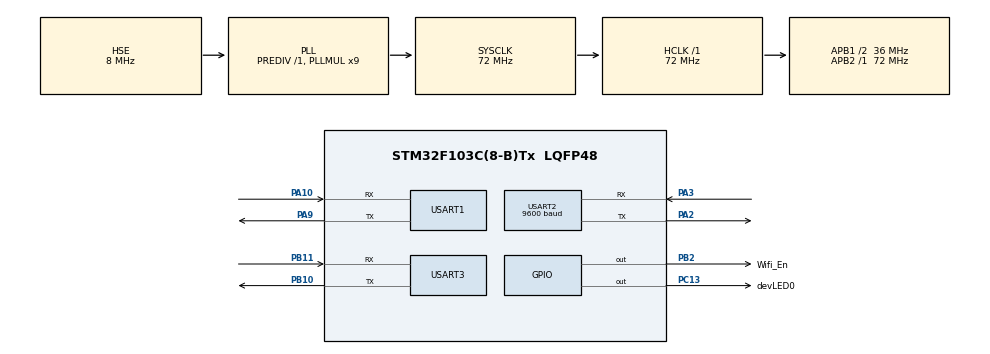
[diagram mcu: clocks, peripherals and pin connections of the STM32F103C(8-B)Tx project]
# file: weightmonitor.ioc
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Dma.Request0=USART1_RX
Dma.Request1=USART1_TX
Dma.Request2=USART3_RX
Dma.Request3=USART3_TX
Dma.Request4=USART2_RX
Dma.Request5=USART2_TX
Dma.USART1_RX.0.Direction=DMA_PERIPH_TO_MEMORY
Dma.USART1_RX.0.Instance=DMA1_Channel5
Dma.USART1_RX.0.MemDataAlignment=DMA_MDATAALIGN_BYTE
Dma.USART1_RX.0.MemInc=DMA_MINC_ENABLE
Dma.USART1_RX.0.Mode=DMA_CIRCULAR
Dma.USART1_RX.0.PeriphDataAlignment=DMA_PDATAALIGN_BYTE
Dma.USART1_RX.0.PeriphInc=DMA_PINC_DISABLE
Dma.USART1_RX.0.Priority=DMA_PRIORITY_LOW
Dma.USART1_TX.1.Direction=DMA_MEMORY_TO_PERIPH
Dma.USART1_TX.1.Instance=DMA1_Channel4
Dma.USART1_TX.1.MemDataAlignment=DMA_MDATAALIGN_BYTE
Dma.USART1_TX.1.MemInc=DMA_MINC_ENABLE
Dma.USART1_TX.1.Mode=DMA_NORMAL
Dma.USART1_TX.1.PeriphDataAlignment=DMA_PDATAALIGN_BYTE
Dma.USART1_TX.1.PeriphInc=DMA_PINC_DISABLE
Dma.USART1_TX.1.Priority=DMA_PRIORITY_LOW
Dma.USART2_RX.4.Direction=DMA_PERIPH_TO_MEMORY
Dma.USART2_RX.4.Instance=DMA1_Channel6
Dma.USART2_RX.4.MemDataAlignment=DMA_MDATAALIGN_BYTE
Dma.USART2_RX.4.MemInc=DMA_MINC_ENABLE
Dma.USART2_RX.4.Mode=DMA_CIRCULAR
Dma.USART2_RX.4.PeriphDataAlignment=DMA_PDATAALIGN_BYTE
Dma.USART2_RX.4.PeriphInc=DMA_PINC_DISABLE
Dma.USART2_RX.4.Priority=DMA_PRIORITY_LOW
Dma.USART2_TX.5.Direction=DMA_MEMORY_TO_PERIPH
Dma.USART2_TX.5.Instance=DMA1_Channel7
Dma.USART2_TX.5.MemDataAlignment=DMA_MDATAALIGN_BYTE
Dma.USART2_TX.5.MemInc=DMA_MINC_ENABLE
Dma.USART2_TX.5.Mode=DMA_NORMAL
Dma.USART2_TX.5.PeriphDataAlignment=DMA_PDATAALIGN_BYTE
Dma.USART2_TX.5.PeriphInc=DMA_PINC_DISABLE
Dma.USART2_TX.5.Priority=DMA_PRIORITY_LOW
Dma.USART3_RX.2.Direction=DMA_PERIPH_TO_MEMORY
Dma.USART3_RX.2.Instance=DMA1_Channel3
Dma.USART3_RX.2.MemDataAlignment=DMA_MDATAALIGN_BYTE
Dma.USART3_RX.2.MemInc=DMA_MINC_ENABLE
Dma.USART3_RX.2.Mode=DMA_CIRCULAR
Dma.USART3_RX.2.PeriphDataAlignment=DMA_PDATAALIGN_BYTE
Dma.USART3_RX.2.PeriphInc=DMA_PINC_DISABLE
Dma.USART3_RX.2.Priority=DMA_PRIORITY_LOW
Dma.USART3_TX.3.Direction=DMA_MEMORY_TO_PERIPH
Dma.USART3_TX.3.Instance=DMA1_Channel2
Dma.USART3_TX.3.MemDataAlignment=DMA_MDATAALIGN_BYTE
Dma.USART3_TX.3.MemInc=DMA_MINC_ENABLE
Dma.USART3_TX.3.Mode=DMA_NORMAL
Dma.USART3_TX.3.PeriphDataAlignment=DMA_PDATAALIGN_BYTE
Dma.USART3_TX.3.PeriphInc=DMA_PINC_DISABLE
Dma.USART3_TX.3.Priority=DMA_PRIORITY_LOW
FREERTOS.BinarySemaphores01=data_t_cplt;wifi_t_cplt;ctrl_t_cplt
FREERTOS.INCLUDE_vTaskDelayUntil=1
FREERTOS.Queues01=data_r_queue,4,uart_memblk_pt,NULL;data_t_queue,4,uart_memblk_pt,NULL;wifi_r_queue,4,uart_memblk_pt ,NULL;wifi_t_queue,4,uart_memblk_pt,NULL;ctrl_r_queue,4,uart_memblk_pt,NULL;ctrl_t_queue,4,uart_memblk_pt ,NULL;datarecv_queue,256,char,NULL;wifirecv_queue,256,char,NULL
FREERTOS.Tasks01=defaultTask,-3,128,StartDefaultTask,Default;recv_data,3,128,func_recv_data,As external;recv_ctrl,3,128,func_recv_ctrl,As external;recv_wifi,3,128,func_recv_wifi,As external;handle_data,1,128,func_handle_data,As external;handle_ctrl,1,128,func_handle_ctrl,As external;handle_wifi,1,128,func_handle_wifi,As external;send_data,2,128,func_send_data,As external;send_ctrl,2,128,func_send_ctrl,As external;send_wifi,2,128,func_send_wifi,As external;mainthread,0,128,func_mainthread,As external
FREERTOS.Timers01=led0,Callback_led0,osTimerOnce,As external
FREERTOS.configMINIMAL_STACK_SIZE=128
FREERTOS.configTIMER_TASK_PRIORITY=3
FREERTOS.configTOTAL_HEAP_SIZE=15360
FREERTOS.configUSE_TIMERS=1
IWDG.Prescaler=IWDG_PRESCALER_256
Mcu.Family=STM32F1
Mcu.Name=STM32F103C(8-B)Tx
Mcu.Package=LQFP48
NVIC.DMA1_Channel2_IRQn=true\:5\:0\:false
NVIC.DMA1_Channel3_IRQn=true\:5\:0\:false
NVIC.DMA1_Channel4_IRQn=true\:5\:0\:false
NVIC.DMA1_Channel5_IRQn=true\:5\:0\:false
NVIC.DMA1_Channel6_IRQn=true\:5\:0\:false
NVIC.DMA1_Channel7_IRQn=true\:5\:0\:false
NVIC.PriorityGroup=NVIC_PRIORITYGROUP_4
NVIC.TIM2_IRQn=true\:0\:0\:false
NVIC.TimeBase=TIM2_IRQn
NVIC.TimeBaseIP=TIM2
NVIC.USART1_IRQn=true\:5\:0\:false
NVIC.USART2_IRQn=true\:5\:0\:false
NVIC.USART3_IRQn=true\:5\:0\:false
PA10.GPIO_PuPd=GPIO_PULLDOWN
PA10.Mode=Asynchronous
PA10.Signal=USART1_RX
PA13.Mode=Serial_Wire
PA13.Signal=SYS_JTMS-SWDIO
PA14.Mode=Serial_Wire
PA14.Signal=SYS_JTCK-SWCLK
PA2.Mode=Asynchronous
PA2.Signal=USART2_TX
PA3.GPIO_PuPd=GPIO_PULLDOWN
PA3.Mode=Asynchronous
PA3.Signal=USART2_RX
PA9.Mode=Asynchronous
PA9.Signal=USART1_TX
PB10.Mode=Asynchronous
PB10.Signal=USART3_TX
PB11.GPIO_PuPd=GPIO_PULLDOWN
PB11.Mode=Asynchronous
PB11.Signal=USART3_RX
PB2.GPIO_Label=Wifi_En
PB2.Signal=GPIO_Output
PC13-TAMPER-RTC.GPIO_Label=devLED0
PC13-TAMPER-RTC.Signal=GPIO_Output
PD0-OSC_IN.Mode=HSE-External-Oscillator
PD0-OSC_IN.Signal=RCC_OSC_IN
PD1-OSC_OUT.Mode=HSE-External-Oscillator
PD1-OSC_OUT.Signal=RCC_OSC_OUT
ProjectManager.HeapSize=0x400
ProjectManager.StackSize=0x200
ProjectManager.TargetToolchain=MDK-ARM V5
RCC.AHBFreq_Value=72000000
RCC.APB1CLKDivider=RCC_HCLK_DIV2
RCC.APB1Freq_Value=36000000
RCC.APB1TimFreq_Value=72000000
RCC.APB2Freq_Value=72000000
RCC.APB2TimFreq_Value=72000000
RCC.HCLKFreq_Value=72000000
RCC.HSIState=RCC_HSI_ON
RCC.PLLMUL=RCC_PLL_MUL9
RCC.PLLSourceVirtual=RCC_PLLSOURCE_HSE
RCC.RTCClockSelection=RCC_RTCCLKSOURCE_LSE
RCC.SYSCLKFreq_VALUE=72000000
RCC.SYSCLKSource=RCC_SYSCLKSOURCE_PLLCLK
RCC.USBFreq_Value=48000000
RCC.USBPrescaler=RCC_USBPLLCLK_DIV1_5
USART2.BaudRate=9600
VP_FREERTOS_VS_ENABLE.Mode=Enabled
VP_IWDG_VS_IWDG.Mode=IWDG_Activate
VP_SYS_VS_tim2.Mode=TIM2
board=weightmonitor

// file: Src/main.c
/**
  ******************************************************************************
  * File Name          : main.c
  * Description        : Main program body
  ******************************************************************************
  *
  * COPYRIGHT(c) 2016 STMicroelectronics
  *
  * Redistribution and use in source and binary forms, with or without modification,
  * are permitted provided that the following conditions are met:
  *   1. Redistributions of source code must retain the above copyright notice,
  *      this list of conditions and the following disclaimer.
  *   2. Redistributions in binary form must reproduce the above copyright notice,
  *      this list of conditions and the following disclaimer in the documentation
  *      and/or other materials provided with the distribution.
  *   3. Neither the name of STMicroelectronics nor the names of its contributors
  *      may be used to endorse or promote products derived from this software
  *      without specific prior written permission.
  *
  * THIS SOFTWARE IS PROVIDED BY THE COPYRIGHT HOLDERS AND CONTRIBUTORS "AS IS"
  * AND ANY EXPRESS OR IMPLIED WARRANTIES, INCLUDING, BUT NOT LIMITED TO, THE
  * IMPLIED WARRANTIES OF MERCHANTABILITY AND FITNESS FOR A PARTICULAR PURPOSE ARE
  * DISCLAIMED. IN NO EVENT SHALL THE COPYRIGHT HOLDER OR CONTRIBUTORS BE LIABLE
  * FOR ANY DIRECT, INDIRECT, INCIDENTAL, SPECIAL, EXEMPLARY, OR CONSEQUENTIAL
  * DAMAGES (INCLUDING, BUT NOT LIMITED TO, PROCUREMENT OF SUBSTITUTE GOODS OR
  * SERVICES; LOSS OF USE, DATA, OR PROFITS; OR BUSINESS INTERRUPTION) HOWEVER
  * CAUSED AND ON ANY THEORY OF LIABILITY, WHETHER IN CONTRACT, STRICT LIABILITY,
  * OR TORT (INCLUDING NEGLIGENCE OR OTHERWISE) ARISING IN ANY WAY OUT OF THE USE
  * OF THIS SOFTWARE, EVEN IF ADVISED OF THE POSSIBILITY OF SUCH DAMAGE.
  *
  ******************************************************************************
  */
#include "stm32f1xx_hal.h"
#include "cmsis_os.h"
#include "dma.h"
#include "iwdg.h"
#include "usart.h"
#include "gpio.h"

/* USER CODE BEGIN Includes */
#include <stdbool.h>
#include "ledctrl.h"
#include "memblk.h"
/* USER CODE END Includes */

/* USER CODE BEGIN PV */
/* Private variables ---------------------------------------------------------*/

/* USER CODE END PV */

void SystemClock_Config(void);
void MX_FREERTOS_Init(void);

/* USER CODE BEGIN PFP */
/* Private function prototypes -----------------------------------------------*/

/* USER CODE END PFP */

int main(void)
{

  /* MCU Configuration----------------------------------------------------------*/

  /* Reset of all peripherals, Initializes the Flash interface and the Systick. */
  HAL_Init();

  /* Configure the system clock */
  SystemClock_Config();

  /* Initialize all configured peripherals */
  MX_GPIO_Init();
  MX_DMA_Init();
  MX_USART2_UART_Init();
  MX_USART3_UART_Init();
  MX_USART1_UART_Init();
  MX_IWDG_Init();

  /* USER CODE BEGIN 2 */

    if(memblk_init() != 0)
        while(true)
            ;

  /* USER CODE END 2 */

  /* Call init function for freertos objects (in freertos.c) */
  MX_FREERTOS_Init();

  /* Start scheduler */
  osKernelStart();

  /* We should never get here as control is now taken by the scheduler */

  /* Infinite loop */
  while (1)
  {

  }

}

/** System Clock Configuration
*/
void SystemClock_Config(void)
{

  RCC_OscInitTypeDef RCC_OscInitStruct;
  RCC_ClkInitTypeDef RCC_ClkInitStruct;

  RCC_OscInitStruct.OscillatorType = RCC_OSCILLATORTYPE_LSI|RCC_OSCILLATORTYPE_HSE;
  RCC_OscInitStruct.HSEState = RCC_HSE_ON;
  RCC_OscInitStruct.HSEPredivValue = RCC_HSE_PREDIV_DIV1;
  RCC_OscInitStruct.LSIState = RCC_LSI_ON;
  RCC_OscInitStruct.PLL.PLLState = RCC_PLL_ON;
  RCC_OscInitStruct.PLL.PLLSource = RCC_PLLSOURCE_HSE;
  RCC_OscInitStruct.PLL.PLLMUL = RCC_PLL_MUL9;
  HAL_RCC_OscConfig(&RCC_OscInitStruct);

  RCC_ClkInitStruct.ClockType = RCC_CLOCKTYPE_HCLK|RCC_CLOCKTYPE_SYSCLK
                              |RCC_CLOCKTYPE_PCLK1|RCC_CLOCKTYPE_PCLK2;
  RCC_ClkInitStruct.SYSCLKSource = RCC_SYSCLKSOURCE_PLLCLK;
  RCC_ClkInitStruct.AHBCLKDivider = RCC_SYSCLK_DIV1;
  RCC_ClkInitStruct.APB1CLKDivider = RCC_HCLK_DIV2;
  RCC_ClkInitStruct.APB2CLKDivider = RCC_HCLK_DIV1;
  HAL_RCC_ClockConfig(&RCC_ClkInitStruct, FLASH_LATENCY_2);

  HAL_SYSTICK_Config(HAL_RCC_GetHCLKFreq()/1000);

  HAL_SYSTICK_CLKSourceConfig(SYSTICK_CLKSOURCE_HCLK);

  /* SysTick_IRQn interrupt configuration */
  HAL_NVIC_SetPriority(SysTick_IRQn, 15, 0);
}

/************************ (C) COPYRIGHT STMicroelectronics *****END OF FILE****/

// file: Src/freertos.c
/**
  ******************************************************************************
  * File Name          : freertos.c
  * Description        : Code for freertos applications
  ******************************************************************************
  *
  * COPYRIGHT(c) 2016 STMicroelectronics
  *
  * Redistribution and use in source and binary forms, with or without modification,
  * are permitted provided that the following conditions are met:
  *   1. Redistributions of source code must retain the above copyright notice,
  *      this list of conditions and the following disclaimer.
  *   2. Redistributions in binary form must reproduce the above copyright notice,
  *      this list of conditions and the following disclaimer in the documentation
  *      and/or other materials provided with the distribution.
  *   3. Neither the name of STMicroelectronics nor the names of its contributors
  *      may be used to endorse or promote products derived from this software
  *      without specific prior written permission.
  *
  * THIS SOFTWARE IS PROVIDED BY THE COPYRIGHT HOLDERS AND CONTRIBUTORS "AS IS"
  * AND ANY EXPRESS OR IMPLIED WARRANTIES, INCLUDING, BUT NOT LIMITED TO, THE
  * IMPLIED WARRANTIES OF MERCHANTABILITY AND FITNESS FOR A PARTICULAR PURPOSE ARE
  * DISCLAIMED. IN NO EVENT SHALL THE COPYRIGHT HOLDER OR CONTRIBUTORS BE LIABLE
  * FOR ANY DIRECT, INDIRECT, INCIDENTAL, SPECIAL, EXEMPLARY, OR CONSEQUENTIAL
  * DAMAGES (INCLUDING, BUT NOT LIMITED TO, PROCUREMENT OF SUBSTITUTE GOODS OR
  * SERVICES; LOSS OF USE, DATA, OR PROFITS; OR BUSINESS INTERRUPTION) HOWEVER
  * CAUSED AND ON ANY THEORY OF LIABILITY, WHETHER IN CONTRACT, STRICT LIABILITY,
  * OR TORT (INCLUDING NEGLIGENCE OR OTHERWISE) ARISING IN ANY WAY OUT OF THE USE
  * OF THIS SOFTWARE, EVEN IF ADVISED OF THE POSSIBILITY OF SUCH DAMAGE.
  *
  ******************************************************************************
  */

#include "FreeRTOS.h"
#include "task.h"
#include "cmsis_os.h"

/* USER CODE BEGIN Includes */
#include "uart_driver.h"
/* USER CODE END Includes */

osThreadId defaultTaskHandle;
osThreadId recv_dataHandle;
osThreadId recv_ctrlHandle;
osThreadId recv_wifiHandle;
osThreadId handle_dataHandle;
osThreadId handle_ctrlHandle;
osThreadId handle_wifiHandle;
osThreadId send_dataHandle;
osThreadId send_ctrlHandle;
osThreadId send_wifiHandle;
osThreadId mainthreadHandle;
osMessageQId data_r_queueHandle;
osMessageQId data_t_queueHandle;
osMessageQId wifi_r_queueHandle;
osMessageQId wifi_t_queueHandle;
osMessageQId ctrl_r_queueHandle;
osMessageQId ctrl_t_queueHandle;
osMessageQId datarecv_queueHandle;
osMessageQId wifirecv_queueHandle;
osTimerId led0Handle;
osSemaphoreId data_t_cpltHandle;
osSemaphoreId wifi_t_cpltHandle;
osSemaphoreId ctrl_t_cpltHandle;

void StartDefaultTask(void const * argument);
extern void func_recv_data(void const * argument);
extern void func_recv_ctrl(void const * argument);
extern void func_recv_wifi(void const * argument);
extern void func_handle_data(void const * argument);
extern void func_handle_ctrl(void const * argument);
extern void func_handle_wifi(void const * argument);
extern void func_send_data(void const * argument);
extern void func_send_ctrl(void const * argument);
extern void func_send_wifi(void const * argument);
extern void func_mainthread(void const * argument);
extern void Callback_led0(void const * argument);

void MX_FREERTOS_Init(void); /* (MISRA C 2004 rule 8.1) */

/* Hook prototypes */

/* Init FreeRTOS */

void MX_FREERTOS_Init(void) {

  /* Create the semaphores(s) */
  /* definition and creation of data_t_cplt */
  osSemaphoreDef(data_t_cplt);
  data_t_cpltHandle = osSemaphoreCreate(osSemaphore(data_t_cplt), 1);

  /* definition and creation of wifi_t_cplt */
  osSemaphoreDef(wifi_t_cplt);
  wifi_t_cpltHandle = osSemaphoreCreate(osSemaphore(wifi_t_cplt), 1);

  /* definition and creation of ctrl_t_cplt */
  osSemaphoreDef(ctrl_t_cplt);
  ctrl_t_cpltHandle = osSemaphoreCreate(osSemaphore(ctrl_t_cplt), 1);

  /* Create the timer(s) */
  /* definition and creation of led0 */
  osTimerDef(led0, Callback_led0);
  led0Handle = osTimerCreate(osTimer(led0), osTimerOnce, NULL);

  /* Create the thread(s) */
  /* definition and creation of defaultTask */
  osThreadDef(defaultTask, StartDefaultTask, osPriorityIdle, 0, 128);
  defaultTaskHandle = osThreadCreate(osThread(defaultTask), NULL);

  /* definition and creation of recv_data */
  osThreadDef(recv_data, func_recv_data, osPriorityRealtime, 0, 128);
  recv_dataHandle = osThreadCreate(osThread(recv_data), NULL);

  /* definition and creation of recv_ctrl */
  osThreadDef(recv_ctrl, func_recv_ctrl, osPriorityRealtime, 0, 128);
  recv_ctrlHandle = osThreadCreate(osThread(recv_ctrl), NULL);

  /* definition and creation of recv_wifi */
  osThreadDef(recv_wifi, func_recv_wifi, osPriorityRealtime, 0, 128);
  recv_wifiHandle = osThreadCreate(osThread(recv_wifi), NULL);

  /* definition and creation of handle_data */
  osThreadDef(handle_data, func_handle_data, osPriorityAboveNormal, 0, 128);
  handle_dataHandle = osThreadCreate(osThread(handle_data), NULL);

  /* definition and creation of handle_ctrl */
  osThreadDef(handle_ctrl, func_handle_ctrl, osPriorityAboveNormal, 0, 128);
  handle_ctrlHandle = osThreadCreate(osThread(handle_ctrl), NULL);

  /* definition and creation of handle_wifi */
  osThreadDef(handle_wifi, func_handle_wifi, osPriorityAboveNormal, 0, 128);
  handle_wifiHandle = osThreadCreate(osThread(handle_wifi), NULL);

  /* definition and creation of send_data */
  osThreadDef(send_data, func_send_data, osPriorityHigh, 0, 128);
  send_dataHandle = osThreadCreate(osThread(send_data), NULL);

  /* definition and creation of send_ctrl */
  osThreadDef(send_ctrl, func_send_ctrl, osPriorityHigh, 0, 128);
  send_ctrlHandle = osThreadCreate(osThread(send_ctrl), NULL);

  /* definition and creation of send_wifi */
  osThreadDef(send_wifi, func_send_wifi, osPriorityHigh, 0, 128);
  send_wifiHandle = osThreadCreate(osThread(send_wifi), NULL);

  /* definition and creation of mainthread */
  osThreadDef(mainthread, func_mainthread, osPriorityNormal, 0, 128);
  mainthreadHandle = osThreadCreate(osThread(mainthread), NULL);

  /* Create the queue(s) */
  /* definition and creation of data_r_queue */
  osMessageQDef(data_r_queue, 4, uart_memblk_pt);
  data_r_queueHandle = osMessageCreate(osMessageQ(data_r_queue), NULL);

  /* definition and creation of data_t_queue */
  osMessageQDef(data_t_queue, 4, uart_memblk_pt);
  data_t_queueHandle = osMessageCreate(osMessageQ(data_t_queue), NULL);

  /* definition and creation of wifi_r_queue */
  osMessageQDef(wifi_r_queue, 4, uart_memblk_pt );
  wifi_r_queueHandle = osMessageCreate(osMessageQ(wifi_r_queue), NULL);

  /* definition and creation of wifi_t_queue */
  osMessageQDef(wifi_t_queue, 4, uart_memblk_pt);
  wifi_t_queueHandle = osMessageCreate(osMessageQ(wifi_t_queue), NULL);

  /* definition and creation of ctrl_r_queue */
  osMessageQDef(ctrl_r_queue, 4, uart_memblk_pt);
  ctrl_r_queueHandle = osMessageCreate(osMessageQ(ctrl_r_queue), NULL);

  /* definition and creation of ctrl_t_queue */
  osMessageQDef(ctrl_t_queue, 4, uart_memblk_pt );
  ctrl_t_queueHandle = osMessageCreate(osMessageQ(ctrl_t_queue), NULL);

  /* definition and creation of datarecv_queue */
  osMessageQDef(datarecv_queue, 256, char);
  datarecv_queueHandle = osMessageCreate(osMessageQ(datarecv_queue), NULL);

  /* definition and creation of wifirecv_queue */
  osMessageQDef(wifirecv_queue, 256, char);
  wifirecv_queueHandle = osMessageCreate(osMessageQ(wifirecv_queue), NULL);

}

/* StartDefaultTask function */
void StartDefaultTask(void const * argument)
{

  for(;;)
  {
    osDelay(1);
  }
}

/************************ (C) COPYRIGHT STMicroelectronics *****END OF FILE****/
